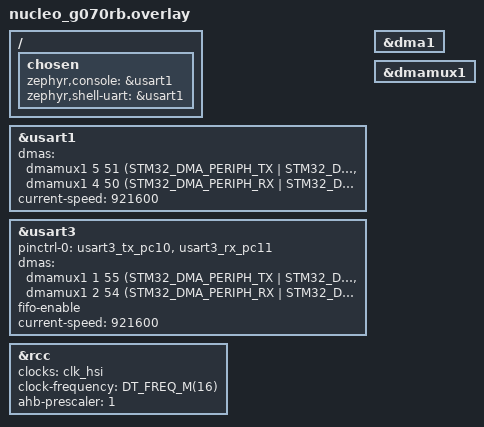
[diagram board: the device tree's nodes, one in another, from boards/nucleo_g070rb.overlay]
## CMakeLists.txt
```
# SPDX-License-Identifier: Apache-2.0

cmake_minimum_required(VERSION 3.20.0)

find_package(Zephyr REQUIRED HINTS $ENV{ZEPHYR_BASE})
project(uart_async_api)

target_sources(app PRIVATE
  src/measure_latency.c
  src/critical_thread.c
  src/rx_thread.c
  src/tx_thread.c
  src/uart_cb.c
)
```

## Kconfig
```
source "Kconfig.zephyr"

config FIX_RXNE_PROBLEM
	bool "Use this for a quick fix of the RXNE problem"
    default n
```

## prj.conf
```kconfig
CONFIG_LOG=y
CONFIG_SERIAL=y
CONFIG_UART_ASYNC_API=y
CONFIG_RING_BUFFER=y

CONFIG_DEBUG=y
CONFIG_LOG_MODE_IMMEDIATE=y
CONFIG_LOG_BUFFER_SIZE=8192

CONFIG_BOOT_BANNER=n

CONFIG_LOG_BACKEND_RTT=y
CONFIG_USE_SEGGER_RTT=y
CONFIG_LOG_BACKEND_RTT_MODE_OVERWRITE=y
CONFIG_LOG_BACKEND_RTT_BUFFER=1
CONFIG_LOG_BACKEND_RTT_BUFFER_SIZE=4096
```

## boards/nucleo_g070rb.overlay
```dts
/*
 * Copyright (c) 2025 STMicroelectronics
 *
 * SPDX-License-Identifier: Apache-2.0
 */

 / {
	// Console RX on PC5 (CN10.37 or CN9.1), Console TX on PC4 (CN10.35 or CN9.2)
 	chosen {
		zephyr,console = &usart1;         /* in zephyr/boards/st/nucleo_g070rb/nucleo_g070rb.dts:19 */
		zephyr,shell-uart = &usart1;      /* in zephyr/boards/st/nucleo_g070rb/nucleo_g070rb.dts:20 */
	};
};

// Other uart RX on PC11 (CN7.2), TX on PC10 (CN7.1)
// Can be looped back with a jumper
&usart1 {
    dmas = <&dmamux1 5 51 (STM32_DMA_PERIPH_TX | STM32_DMA_PRIORITY_LOW)>,
           <&dmamux1 4 50 (STM32_DMA_PERIPH_RX | STM32_DMA_PRIORITY_LOW)>;
    dma-names = "tx", "rx";
    current-speed = <921600>;
};

&usart3 {
    pinctrl-0 = <&usart3_tx_pc10 &usart3_rx_pc11>;
    pinctrl-names = "default";
    dmas = <&dmamux1 1 55 (STM32_DMA_PERIPH_TX | STM32_DMA_PRIORITY_LOW)>,
           <&dmamux1 2 54 (STM32_DMA_PERIPH_RX | STM32_DMA_PRIORITY_VERY_HIGH | STM32_DMA_MODE_CYCLIC)>;
    dma-names = "tx", "rx";
	fifo-enable;
	current-speed = <921600>;
	status = "okay";
};

&dma1 {
	status = "okay";
};

&dmamux1 {
	status = "okay";
};

&rcc {
	clocks = <&clk_hsi>;
	clock-frequency = <DT_FREQ_M(16)>;
	ahb-prescaler = <1>;
};
```

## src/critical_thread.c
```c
/*
 * Copyright (c) 2025 Embeint Inc
 *
 * SPDX-License-Identifier: Apache-2.0
 */

#include <zephyr/kernel.h>
#include <zephyr/logging/log.h>
LOG_MODULE_DECLARE(sample, LOG_LEVEL_INF);

#define CRITICAL_THREAD_BUSY_TIME_MS  500
#define CRITICAL_THREAD_SLEEP_TIME_MS 60000

/**
 * This task is waken periodically to simulate some critical operations that preempt the main task.
 * Increase CRITICAL_THREAD_BUSY_TIME_MS to increase the odds of overflowing the main's RX ring buffer
 * and trigger the recovery mechanism.
 */
static void critical_thread_fn(void *a, void *b, void *c)
{
	ARG_UNUSED(a);
	ARG_UNUSED(b);
	ARG_UNUSED(c);

	LOG_INF("");
	LOG_INF("----- critical thread started -----");
	LOG_INF("Busy %d ms every %d ms",
		CRITICAL_THREAD_BUSY_TIME_MS, CRITICAL_THREAD_SLEEP_TIME_MS);

	while (1) {
        k_msleep(CRITICAL_THREAD_SLEEP_TIME_MS);

		LOG_WRN("Critical thread: Enter busy wait");

		k_timepoint_t deadline = sys_timepoint_calc(K_MSEC(CRITICAL_THREAD_BUSY_TIME_MS));
		while (!sys_timepoint_expired(deadline)) {
			k_busy_wait(1);
			k_yield(); // Allow the log task to run, for convenience
		}

		LOG_WRN("Critical thread: Leave busy wait");
	}
}

// Should be higher prio than rx thread, but lower than tx
#define CRITICAL_THREAD_PRIORITY      1
K_THREAD_DEFINE(critical_thread, 1024, critical_thread_fn, NULL, NULL, NULL, CRITICAL_THREAD_PRIORITY, 0, 0);
```

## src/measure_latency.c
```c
/*
 * Copyright (c) 2025 Embeint Inc
 *
 * SPDX-License-Identifier: Apache-2.0
 */

#include <zephyr/kernel.h>
#include <zephyr/device.h>
#include <zephyr/drivers/uart.h>
#include <string.h>

#include <zephyr/logging/log.h>
LOG_MODULE_DECLARE(sample, LOG_LEVEL_INF);

#define MEASURE_BYTES 100
#define BAUDRATE DT_PROP(DT_NODELABEL(usart3), current_speed)

static const struct device *const uart_dev = DEVICE_DT_GET(DT_NODELABEL(usart3));

static struct k_sem tx_done_sem;
static uint32_t t0, t2;
static volatile uint32_t t1;

static void temp_uart_callback(const struct device *dev, struct uart_event *evt, void *user_data)
{
	ARG_UNUSED(dev);
	ARG_UNUSED(user_data);
	if (evt->type == UART_TX_DONE) {
		t1 = k_cycle_get_32();
		k_sem_give(&tx_done_sem);
	}
}

static int measure_latency_init(void)
{
	uint8_t buf[MEASURE_BYTES];
	uint64_t elapsed_ns, theoretical_ns, overhead_ns, isr_exit_ns;
	int rc;

	memset(buf, 'X', sizeof(buf));
	k_sem_init(&tx_done_sem, 0, 1);
	uart_callback_set(uart_dev, temp_uart_callback, NULL);

	t0 = k_cycle_get_32();
	rc = uart_tx(uart_dev, buf, sizeof(buf), SYS_FOREVER_US);
	if (rc != 0) {
		LOG_WRN("Latency: uart_tx failed (%d)", rc);
		return 0;
	}

	if (k_sem_take(&tx_done_sem, K_FOREVER) != 0) {
		LOG_WRN("Latency: TX_DONE timeout");
		return 0;
	}
	t2 = k_cycle_get_32();

	elapsed_ns = k_cyc_to_ns_floor64(t1 - t0);
	isr_exit_ns = k_cyc_to_ns_floor64(t2 - t1);

	/* 8N1: 1 start + 8 data + 1 stop = 10 bits per byte */
	theoretical_ns = (uint64_t)MEASURE_BYTES * 10ULL * 1000000000ULL / BAUDRATE;
	overhead_ns = elapsed_ns - theoretical_ns;

	LOG_INF("");
	LOG_INF("----- UART LATENCY TEST -----");

	LOG_INF("UART TX latency @ %u baud, %d bytes:", BAUDRATE, MEASURE_BYTES);
	LOG_INF("  theoretical : %u us", (uint32_t)(theoretical_ns / 1000U));
	LOG_INF("  elapsed     : %u us", (uint32_t)(elapsed_ns / 1000U));
	LOG_INF("");
	LOG_INF("  Measured ISR exit latency   : %u us", (uint32_t)(isr_exit_ns / 1000U));
	LOG_INF("  Calculated ISR exit latency : %u us", (uint32_t)(overhead_ns / 1000U));
	LOG_INF("  Time between bytes		 : %u us", (uint32_t)(elapsed_ns / 1000U / MEASURE_BYTES));
	LOG_INF("  (Problems start when ISR latency gets close to time per byte)");

	// Restore uart how it was...
	uart_callback_set(uart_dev, NULL, NULL);

	return 0;
}

// First thing to run, optionnal test to measure latencies
// You can also run zephyr/tests/benchmarks/latency_measure to get more accurate latency measurements.
#define MEASURE_LATENCY_INIT_PRIORITY 0
SYS_INIT(measure_latency_init, APPLICATION, MEASURE_LATENCY_INIT_PRIORITY);
```

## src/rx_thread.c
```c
/*
 * Copyright (c) 2025 Embeint Inc
 *
 * SPDX-License-Identifier: Apache-2.0
 */

#include <zephyr/kernel.h>
#include <zephyr/device.h>
#include <zephyr/drivers/uart.h>
#include <zephyr/sys/ring_buffer.h>

#include <zephyr/logging/log.h>
LOG_MODULE_REGISTER(sample, LOG_LEVEL_INF);

#include "uart_cb.h"

#define RX_RING_BUF_SIZE 8192
RING_BUF_DECLARE(rx_ring_buf, RX_RING_BUF_SIZE);

enum rx_decode_state {
	RX_DECODE_HEADER_0,
	RX_DECODE_HEADER_1,
	RX_DECODE_LEN_0,
	RX_DECODE_LEN_1,
	RX_DECODE_COUNTER_0,
	RX_DECODE_COUNTER_1,
	RX_DECODE_COUNTER_2,
	RX_DECODE_COUNTER_3,
	RX_DECODE_PAYLOAD,
};

static volatile bool rx_recovery_pending;
static enum rx_decode_state rx_state;
static uint16_t rx_expected_len;
static uint16_t rx_payload_pos;
static uint32_t rx_frame_counter;

static uint32_t rx_valid_frames;
static uint32_t rx_last_frame_id;
static uint32_t rx_frames_before_recovery;
static bool rx_report_pending;

static void decode_frame_reset(void);

void on_rx_rdy(const struct uart_event *evt)
{
	uint32_t written;

	written = ring_buf_put(&rx_ring_buf,
			      evt->data.rx.buf + evt->data.rx.offset,
			      evt->data.rx.len);
	if (written < evt->data.rx.len && rx_recovery_pending == false) {
		LOG_WRN("    RX ISR : ring buffer overflow");
		rx_recovery_pending = true;
	}
}

static int uart_rx_recover(void)
{
	int rc;

	LOG_WRN("RX recovery triggered, disabling RX");

	rc = uart_rx_disable(uart_dev);
	if (rc != 0) {
		LOG_ERR("RX disable failed (%d)", rc);
	}

	rc = k_sem_take(&rx_disabled_sem, K_MSEC(100));
	if (rc != 0) {
		LOG_ERR("timeout waiting RX disabled");
	}

	/**
	 * You would expect this to be kind of a "quiet" state (data always incoming, 
	 * but receiver not active), but actually, uart_rx_disable() activates the RXNE and ERROR
	 * interrupts, which causes way more ISRs than the MCU can handle. We explicitely need
	 * the async API because we would not be able to manage 1 interrupt per byte.
	 */

	LOG_ERR("LOGS is red are gonna be very sluggish...");
	LOG_ERR("This is because we disabled the async RX, but the receiver isn't really disabled...");
	LOG_ERR("Instead of receiving 1 interrupt per 500 bytes, we receive 1 per byte, and this MCU can't handle that many interrupts");
	LOG_ERR("Flushing buffers...");

	rx_recovery_pending = false;
	rx_frames_before_recovery = rx_valid_frames;
	rx_valid_frames = 0;
	rx_report_pending = true;
	decode_frame_reset();

	ring_buf_reset(&rx_ring_buf);

	LOG_ERR("Enabling RX back..............");

	rc = uart_rx_enable(uart_dev, rx_ring_buf.buffer, RX_RING_BUF_SIZE, 0);
	if (rc != 0) {
		LOG_ERR("RX re-enable failed (%d)", rc);
	} else {
		LOG_WRN("RX restored");
	}

	return rc;
}

static void decode_frame_reset(void)
{
	rx_expected_len = 0;
	rx_payload_pos = 0;
	rx_frame_counter = 0;
	rx_state = RX_DECODE_HEADER_0;
}

extern int uart3_isr, uart3_rxne, uart3_error;
extern uint32_t tx_elapsed_us;
extern uint32_t tx_estimated_us;
static void decode_frame(uint8_t byte)
{
	switch (rx_state) {
	case RX_DECODE_HEADER_0:
		if (byte == ':') {
			rx_state = RX_DECODE_HEADER_1;
		}
		break;

	case RX_DECODE_HEADER_1:
		rx_state = (byte == ':') ? RX_DECODE_LEN_0 : RX_DECODE_HEADER_0;
		break;

	case RX_DECODE_LEN_0:
		rx_expected_len = byte;
		rx_payload_pos = 0;
		rx_frame_counter = 0;
		rx_state = RX_DECODE_LEN_1;
		break;

	case RX_DECODE_LEN_1:
		rx_expected_len |= ((uint16_t)byte << 8);

		if (rx_expected_len == 0U) {
			LOG_WRN("Received empty frame");
			decode_frame_reset();
			break;
		}

		rx_state = RX_DECODE_COUNTER_0;
		break;

	case RX_DECODE_COUNTER_0:
		rx_frame_counter = byte;
		rx_state = RX_DECODE_COUNTER_1;
		break;

	case RX_DECODE_COUNTER_1:
		rx_frame_counter |= ((uint32_t)byte << 8);
		rx_state = RX_DECODE_COUNTER_2;
		break;

	case RX_DECODE_COUNTER_2:
		rx_frame_counter |= ((uint32_t)byte << 16);
		rx_state = RX_DECODE_COUNTER_3;
		break;

	case RX_DECODE_COUNTER_3:
		rx_frame_counter |= ((uint32_t)byte << 24);
		rx_state = RX_DECODE_PAYLOAD;
		break;

	case RX_DECODE_PAYLOAD:
		rx_payload_pos++;

		while (rx_payload_pos < rx_expected_len) {
			uint8_t *payload;
			uint16_t remaining = rx_expected_len - rx_payload_pos;
			uint32_t claimed = ring_buf_get_claim(&rx_ring_buf, &payload, remaining);

			if (claimed == 0U) {
				break;
			}

			(void)ring_buf_get_finish(&rx_ring_buf, claimed);
			rx_payload_pos += (uint16_t)claimed;
		}

		if (rx_payload_pos >= rx_expected_len) {
			if (rx_report_pending) {
				uint32_t skipped = rx_frame_counter - rx_last_frame_id - 1;
				LOG_WRN("Last cycle got : %u valid frames, %u skipped frames. Tx up for %d%% of the time.",
					rx_frames_before_recovery, skipped,
					tx_elapsed_us ? tx_estimated_us * 100U / tx_elapsed_us : 0U);
				LOG_WRN("UART got : %d interrupts, including %d rxne and %d errors",
					(int)uart3_isr, (int)uart3_rxne, (int)uart3_error);

				uart3_isr = 0;
				uart3_rxne = 0;
				uart3_error = 0;
				rx_report_pending = false;
			}

			rx_valid_frames++;
			rx_last_frame_id = rx_frame_counter;

			/*if (rx_valid_frames % 10 == 0) {
				LOG_INF("RX frame %d to %d",
					(int)rx_frame_counter - 9, (int)rx_frame_counter);
			}*/
			LOG_INF("RX frame %d", rx_frame_counter);

			decode_frame_reset();
		}
		break;

	default:
		decode_frame_reset();
		break;
	}
}

static void rx_thread_fn(void *p1, void *p2, void *p3)
{
	ARG_UNUSED(p1);
	ARG_UNUSED(p2);
	ARG_UNUSED(p3);

	LOG_INF("");
	LOG_INF("----- rx thread started -----");

	/* Enable RX once at startup */
	if (uart_rx_enable(uart_dev, rx_ring_buf.buffer, RX_RING_BUF_SIZE, 0) != 0) {
		LOG_ERR("RX enable failed");
		return;
	}

	while (1) {
		uint8_t byte;

		k_sem_take(&rx_data_sem, K_FOREVER);

		while (!rx_recovery_pending && ring_buf_get(&rx_ring_buf, &byte, 1) == 1) {
			decode_frame(byte);
		}

		if (rx_recovery_pending) {
			(void)uart_rx_recover();
		}
	}
}

#define RX_THREAD_PRIORITY 2
K_THREAD_DEFINE(rx_thread, 2048, rx_thread_fn, NULL, NULL, NULL, RX_THREAD_PRIORITY, 0, 0);
```

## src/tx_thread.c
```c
/*
 * Copyright (c) 2025 Embeint Inc
 *
 * SPDX-License-Identifier: Apache-2.0
 */

#include <zephyr/kernel.h>
#include <zephyr/device.h>
#include <zephyr/drivers/uart.h>
#include <string.h>

#include <zephyr/logging/log.h>
LOG_MODULE_DECLARE(sample, LOG_LEVEL_INF);

#include "uart_cb.h"

#define LOREM_IPSUM "Lorem ipsum dolor sit amet, consectetur adipiscing elit, sed do eiusmod " \
	"tempor incididunt ut labore et dolore magna aliqua. Ut enim ad minim " \
	"veniam, quis nostrud exercitation ullamco laboris nisi ut aliquip ex ea " \
	"commodo consequat. Duis aute irure dolor in reprehenderit in voluptate " \
	"velit esse cillum dolore eu fugiat nulla pariatur. Excepteur sint occaecat " \
	"cupidatat non proident, sunt in culpa qui officia deserunt mollit anim " \
	"id est laborum."

#define TX_PAYLOAD_MIN     	(sizeof(lorem_ipsum) - 1) 	// 445
#define TX_PAYLOAD_MAX     	(sizeof(lorem_ipsum) - 1) 	// 445

#define TX_HEADER_SIZE     	8U
#define TX_BUFFER_SIZE  	(TX_HEADER_SIZE + TX_PAYLOAD_MAX) // 453

#define TX_BAUDRATE        DT_PROP(DT_NODELABEL(usart3), current_speed)
#define TX_MEAN_FRAME_BYTES (TX_HEADER_SIZE + (TX_PAYLOAD_MIN + TX_PAYLOAD_MAX) / 2U)
#define TX_FRAME_TIME_US   (TX_MEAN_FRAME_BYTES * 10U * 1000000U / TX_BAUDRATE)

static const char lorem_ipsum[] = LOREM_IPSUM;
static char tx_buffer[TX_BUFFER_SIZE];
static size_t tx_frame_len;

static uint32_t tx_counter;
static uint32_t tx_last_cycle;
uint32_t tx_elapsed_us;
uint32_t tx_estimated_us;

void on_tx_done(void)
{
	uint32_t now = k_cycle_get_32();
	uint32_t frame_counter = tx_counter++;

	tx_elapsed_us = k_cyc_to_us_floor32(now - tx_last_cycle);
	tx_last_cycle = now;

	tx_buffer[4] = (uint8_t)(frame_counter & 0xFF);
	tx_buffer[5] = (uint8_t)((frame_counter >> 8) & 0xFF);
	tx_buffer[6] = (uint8_t)((frame_counter >> 16) & 0xFF);
	tx_buffer[7] = (uint8_t)((frame_counter >> 24) & 0xFF);

	uart_tx(uart_dev, tx_buffer, tx_frame_len, SYS_FOREVER_US);
}

static int tx_init(void)
{
	int payload_len = sizeof(lorem_ipsum) - 1;

	memcpy(&tx_buffer[TX_HEADER_SIZE], lorem_ipsum, payload_len);

	tx_buffer[0] = ':';
	tx_buffer[1] = ':';
	tx_buffer[2] = (uint8_t)(payload_len & 0xFF);
	tx_buffer[3] = (uint8_t)((payload_len >> 8) & 0xFF);
	tx_buffer[4] = 0;
	tx_buffer[5] = 0;
	tx_buffer[6] = 0;
	tx_buffer[7] = 0;

	tx_frame_len = payload_len + TX_HEADER_SIZE;
	tx_estimated_us = (uint32_t)((uint64_t)tx_frame_len * 10ULL * 1000000ULL / TX_BAUDRATE);

	LOG_INF("");
	LOG_INF("----- TX INIT -----");
	LOG_INF("TX: frame %u B at %u baud, estimated %u us",
		(uint32_t)tx_frame_len, (uint32_t)TX_BAUDRATE, tx_estimated_us);

	tx_last_cycle = k_cycle_get_32();
	on_tx_done();
	return 0;
}

#define TX_INIT_PRIORITY 2
SYS_INIT(tx_init, APPLICATION, TX_INIT_PRIORITY);
```

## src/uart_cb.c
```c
/*
 * Copyright (c) 2025 Embeint Inc
 *
 * SPDX-License-Identifier: Apache-2.0
 */

#include <zephyr/kernel.h>
#include <zephyr/device.h>
#include <zephyr/drivers/uart.h>

#include <zephyr/logging/log.h>
LOG_MODULE_DECLARE(sample, LOG_LEVEL_INF);

#include "uart_cb.h"

const struct device *const uart_dev = DEVICE_DT_GET(DT_NODELABEL(usart3));
K_SEM_DEFINE(rx_data_sem, 0, UINT_MAX);
K_SEM_DEFINE(rx_disabled_sem, 0, UINT_MAX);

extern void on_tx_done(void);
extern void on_rx_rdy(const struct uart_event *evt);

static void uart_cb(const struct device *dev, struct uart_event *evt, void *user_data)
{
	switch (evt->type) {
	case UART_TX_DONE:
		on_tx_done();
		break;
	case UART_RX_RDY:
		//LOG_INF("    RX ISR offset %d, len %d", evt->data.rx.offset, evt->data.rx.len);
		on_rx_rdy(evt);
		k_sem_give(&rx_data_sem);
		break;
	case UART_RX_DISABLED:
		k_sem_give(&rx_disabled_sem);
		break;
	case UART_RX_BUF_REQUEST:
	case UART_RX_BUF_RELEASED:
		break;
	default:
		LOG_WRN("Unhandled UART event %d", evt->type);
	}

	ARG_UNUSED(dev);
	ARG_UNUSED(user_data);
}

static int uart_cb_init(void)
{
	LOG_INF("");
	LOG_INF("----- UART callback init -----");
	return uart_callback_set(uart_dev, uart_cb, NULL);
}

#define UART_CB_INIT_PRIORITY 1
SYS_INIT(uart_cb_init, APPLICATION, UART_CB_INIT_PRIORITY);
```

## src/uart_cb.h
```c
/*
 * Copyright (c) 2025 Embeint Inc
 *
 * SPDX-License-Identifier: Apache-2.0
 */

#ifndef UART_CB_H
#define UART_CB_H

#include <zephyr/device.h>
#include <zephyr/kernel.h>

extern const struct device *const uart_dev;
extern struct k_sem rx_data_sem;
extern struct k_sem rx_disabled_sem;

#endif /* UART_CB_H */
```
